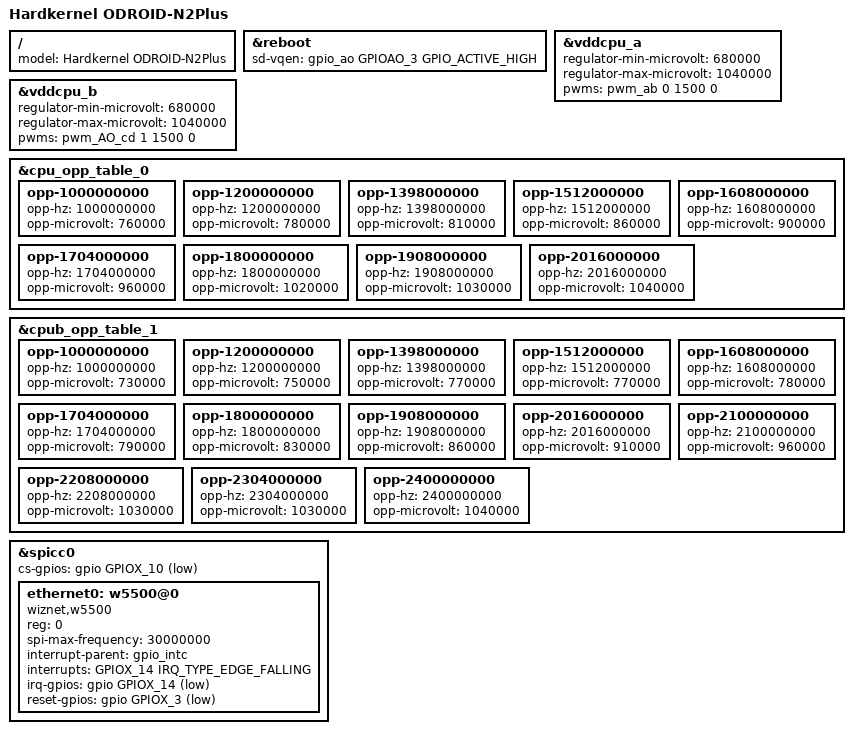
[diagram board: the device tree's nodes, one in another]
// SPDX-License-Identifier: (GPL-2.0+ OR MIT)
/*
 * Copyright (c) 2020 Dongjin Kim <tobetter@gmail.com>
 *
 */

/dts-v1/;

#include "meson-g12b-odroid-n2-plus.dts"
#include "meson64_odroidn2.dtsi"

/ {
	model = "Hardkernel ODROID-N2Plus";
};

&reboot {
	sd-vqen = <&gpio_ao GPIOAO_3 GPIO_ACTIVE_HIGH>;
};

&vddcpu_a {
	regulator-min-microvolt = <680000>;
	regulator-max-microvolt = <1040000>;

	pwms = <&pwm_ab 0 1500 0>;
};

&vddcpu_b {
	regulator-min-microvolt = <680000>;
	regulator-max-microvolt = <1040000>;

	pwms = <&pwm_AO_cd 1 1500 0>;
};

&cpu_opp_table_0 {
	/delete-node/ opp-100000000;
	/delete-node/ opp-250000000;
	/delete-node/ opp-500000000;
	/delete-node/ opp-667000000;
	opp-1000000000 {
		opp-hz = /bits/ 64 <1000000000>;
		opp-microvolt = <760000>;
	};
	opp-1200000000 {
		opp-hz = /bits/ 64 <1200000000>;
		opp-microvolt = <780000>;
	};
	opp-1398000000 {
		opp-hz = /bits/ 64 <1398000000>;
		opp-microvolt = <810000>;
	};
	opp-1512000000 {
		opp-hz = /bits/ 64 <1512000000>;
		opp-microvolt = <860000>;
	};
	opp-1608000000 {
		opp-hz = /bits/ 64 <1608000000>;
		opp-microvolt = <900000>;
	};
	opp-1704000000 {
		opp-hz = /bits/ 64 <1704000000>;
		opp-microvolt = <960000>;
	};
	opp-1800000000 {
		opp-hz = /bits/ 64 <1800000000>;
		opp-microvolt = <1020000>;
	};
	opp-1908000000 {
		opp-hz = /bits/ 64 <1908000000>;
		opp-microvolt = <1030000>;
	};
	opp-2016000000 {
		opp-hz = /bits/ 64 <2016000000>;
		opp-microvolt = <1040000>;
	};
};

&cpub_opp_table_1 {
	/delete-node/ opp-100000000;
	/delete-node/ opp-250000000;
	/delete-node/ opp-500000000;
	/delete-node/ opp-667000000;
	opp-1000000000 {
		opp-hz = /bits/ 64 <1000000000>;
		opp-microvolt = <730000>;
	};
	opp-1200000000 {
		opp-hz = /bits/ 64 <1200000000>;
		opp-microvolt = <750000>;
	};
	opp-1398000000 {
		opp-hz = /bits/ 64 <1398000000>;
		opp-microvolt = <770000>;
	};
	opp-1512000000 {
		opp-hz = /bits/ 64 <1512000000>;
		opp-microvolt = <770000>;
	};
	opp-1608000000 {
		opp-hz = /bits/ 64 <1608000000>;
		opp-microvolt = <780000>;
	};
	opp-1704000000 {
		opp-hz = /bits/ 64 <1704000000>;
		opp-microvolt = <790000>;
	};
	opp-1800000000 {
		opp-hz = /bits/ 64 <1800000000>;
		opp-microvolt = <830000>;
	};
	opp-1908000000 {
		opp-hz = /bits/ 64 <1908000000>;
		opp-microvolt = <860000>;
	};
	opp-2016000000 {
		opp-hz = /bits/ 64 <2016000000>;
		opp-microvolt = <910000>;
	};
	opp-2100000000 {
		opp-hz = /bits/ 64 <2100000000>;
		opp-microvolt = <960000>;
	};
	opp-2208000000 {
		opp-hz = /bits/ 64 <2208000000>;
		opp-microvolt = <1030000>;
	};
	opp-2304000000 {
		opp-hz = /bits/ 64 <2304000000>;
		opp-microvolt = <1030000>;
	};
	opp-2400000000 {
		opp-hz = /bits/ 64 <2400000000>;
		opp-microvolt = <1040000>;
	};
};

&spicc0 {
	status = "okay";
	#address-cells = <1>;
	#size-cells = <0>;

	cs-gpios = <&gpio GPIOX_10 GPIO_ACTIVE_LOW>;

	ethernet0: w5500@0 {
		status = "okay";
		compatible = "wiznet,w5500";
		reg = <0>;
		spi-max-frequency = <30000000>;

/*
pinctrl-names = "default";
pinctrl-0 = <&pinctrl_mikrobus1_int &pinctrl_mikrobus1_rst>;
*/

		interrupt-parent = <&gpio_intc>;
		interrupts = <GPIOX_14 IRQ_TYPE_EDGE_FALLING>;

		irq-gpios = <&gpio GPIOX_14 GPIO_ACTIVE_LOW>;
		reset-gpios = <&gpio GPIOX_3 GPIO_ACTIVE_LOW>;
	};
};
